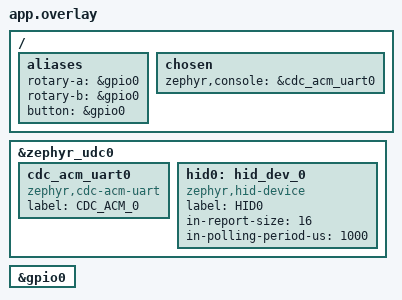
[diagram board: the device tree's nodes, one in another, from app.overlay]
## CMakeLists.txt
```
cmake_minimum_required(VERSION 3.20.0)
find_package(Zephyr)
project(wknb)

target_sources(app PRIVATE src/main.c)
```

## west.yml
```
manifest:
  version: 0.12

  remotes:
    - name: zephyrproject-rtos
      url-base: https://github.com/zephyrproject-rtos

  projects:
    - name: zephyr
      remote: zephyrproject-rtos
      revision: v4.1.0
      import: true  # will auto-fetch all Zephyr dependencies

  self:
    path: app  # <-- path to your application code
```

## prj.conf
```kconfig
# Debug Configuration - USB HID + CDC ACM Console

# USB Device Support
CONFIG_USB_DEVICE_STACK=y
CONFIG_USB_DEVICE_HID=y
CONFIG_USB_DEVICE_PRODUCT="WKNB - Wake Knob Debug"
CONFIG_USB_DEVICE_MANUFACTURER="Cyan Delta"
CONFIG_USB_DEVICE_VID=0xF055
CONFIG_USB_DEVICE_PID=0x2201
CONFIG_USB_SELF_POWERED=y
CONFIG_USB_COMPOSITE_DEVICE=y
CONFIG_USB_DEVICE_REMOTE_WAKEUP=y

# GPIO Support
CONFIG_GPIO=y
CONFIG_GPIO_ENABLE_DISABLE_INTERRUPT=y

# Enable printk and logging for debugging
CONFIG_CONSOLE=y
CONFIG_LOG=y
CONFIG_PRINTK=y

# USB CDC ACM Console (via micro-USB port)
CONFIG_SERIAL=y
CONFIG_USB_CDC_ACM=y

# Debug build flag
CONFIG_DEBUG=y
```

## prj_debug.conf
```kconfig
# Debug Configuration - USB HID + CDC ACM Console

# USB Device Support
CONFIG_USB_DEVICE_STACK=y
CONFIG_USB_DEVICE_HID=y
CONFIG_USB_DEVICE_PRODUCT="WKNB - Wake Knob Debug"
CONFIG_USB_DEVICE_MANUFACTURER="Cyan Delta"
CONFIG_USB_DEVICE_VID=0xF055
CONFIG_USB_DEVICE_PID=0x2201
CONFIG_USB_SELF_POWERED=y
CONFIG_USB_COMPOSITE_DEVICE=y

# GPIO Support
CONFIG_GPIO=y
CONFIG_GPIO_ENABLE_DISABLE_INTERRUPT=y

# Enable printk and logging for debugging
CONFIG_CONSOLE=y
CONFIG_LOG=y
CONFIG_PRINTK=y

# USB CDC ACM Console (via micro-USB port)
CONFIG_SERIAL=y
CONFIG_USB_CDC_ACM=y

# Debug build flag
CONFIG_DEBUG=y
```

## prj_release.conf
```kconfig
# Release Configuration - USB HID Only

# USB Device Support
CONFIG_USB_DEVICE_STACK=y
CONFIG_USB_DEVICE_HID=y
CONFIG_USB_DEVICE_PRODUCT="WKNB - Wake Knob"
CONFIG_USB_DEVICE_MANUFACTURER="Cyan Delta"
CONFIG_USB_DEVICE_VID=0xF055
CONFIG_USB_DEVICE_PID=0x2201
CONFIG_USB_SELF_POWERED=y
CONFIG_USB_DEVICE_REMOTE_WAKEUP=y

# GPIO Support
CONFIG_GPIO=y
CONFIG_GPIO_ENABLE_DISABLE_INTERRUPT=y

# Disable debugging features for release
# CONFIG_CONSOLE is not set
# CONFIG_LOG is not set
# CONFIG_PRINTK is not set

# No CDC ACM in release mode
# CONFIG_SERIAL is not set
# CONFIG_USB_CDC_ACM is not set
# CONFIG_USB_COMPOSITE_DEVICE is not set
```

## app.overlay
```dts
/ {
    aliases {
        rotary-a = &gpio0;
        rotary-b = &gpio0;
        button = &gpio0;
    };

    chosen {
        zephyr,console = &cdc_acm_uart0;
    };
};

&zephyr_udc0 {
    status = "okay";
    
    cdc_acm_uart0: cdc_acm_uart0 {
        compatible = "zephyr,cdc-acm-uart";
        label = "CDC_ACM_0";
    };
    
    hid0: hid_dev_0 {
        compatible = "zephyr,hid-device";
        label = "HID0";
        in-report-size = <16>;
        in-polling-period-us = <1000>;
    };
};

&gpio0 {
    status = "okay";
};
```

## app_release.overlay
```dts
/ {
    aliases {
        rotary-a = &gpio0;
        rotary-b = &gpio0;
        button = &gpio0;
    };
};

&zephyr_udc0 {
    status = "okay";
    
    hid0: hid_dev_0 {
        compatible = "zephyr,hid-device";
        label = "HID0";
        in-report-size = <16>;
        in-polling-period-us = <1000>;
    };
};

&gpio0 {
    status = "okay";
};
```

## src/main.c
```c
#include <zephyr/device.h>
#include <zephyr/drivers/gpio.h>
#include <zephyr/kernel.h>
#include <zephyr/usb/class/usb_hid.h>
#include <zephyr/usb/usb_device.h>

#ifdef CONFIG_DEBUG
#define DEBUG_PRINT(fmt, ...) printk(fmt, ##__VA_ARGS__)
#else
#define DEBUG_PRINT(fmt, ...)                                                  \
  do {                                                                         \
  } while (0)
#endif

#define ROTARY_A_PIN 14
#define ROTARY_B_PIN 15
#define BUTTON_PIN 16
#define LED_PIN 25

#define NUMBER_OF_DETENTS_PER_REPORT 6
#define LONG_PRESS_DURATION_MS 2000

static const struct gpio_dt_spec rotary_a = {
    .port = DEVICE_DT_GET(DT_NODELABEL(gpio0)),
    .pin = ROTARY_A_PIN,
    .dt_flags = GPIO_PULL_UP};
static const struct gpio_dt_spec rotary_b = {
    .port = DEVICE_DT_GET(DT_NODELABEL(gpio0)),
    .pin = ROTARY_B_PIN,
    .dt_flags = GPIO_PULL_UP};
static const struct gpio_dt_spec button = {
    .port = DEVICE_DT_GET(DT_NODELABEL(gpio0)),
    .pin = BUTTON_PIN,
    .dt_flags = GPIO_PULL_UP};
static const struct gpio_dt_spec led = {.port =
                                            DEVICE_DT_GET(DT_NODELABEL(gpio0)),
                                        .pin = LED_PIN,
                                        .dt_flags = GPIO_ACTIVE_HIGH};

static const struct device *hid_dev;
static int last_rotary_state = 0;
static int led_blink_count = 0;
static int detent_counter = 0;
static bool usb_suspended = false;
static struct gpio_callback button_cb_data;
static int64_t last_activity_time = 0;
static struct k_work_delayable long_press_work;
static bool button_pressed_flag = false;
static int64_t button_press_time = 0;

// HID Report Descriptor for Consumer Control (volume/media keys) and System
// Control (suspend)
static const uint8_t hid_report_desc[] = {
    // Consumer Control Collection
    0x05, 0x0C,       // USAGE_PAGE (Consumer Devices)
    0x09, 0x01,       // USAGE (Consumer Control)
    0xA1, 0x01,       // COLLECTION (Application)
    0x85, 0x01,       //   REPORT_ID (1)
    0x15, 0x00,       //   LOGICAL_MINIMUM (0)
    0x26, 0x9C, 0x02, //   LOGICAL_MAXIMUM (668)
    0x19, 0x00,       //   USAGE_MINIMUM (0)
    0x2A, 0x9C, 0x02, //   USAGE_MAXIMUM (668)
    0x75, 0x10,       //   REPORT_SIZE (16)
    0x95, 0x01,       //   REPORT_COUNT (1)
    0x81, 0x00,       //   INPUT (Data,Array,Abs)
    0xC0,             // END_COLLECTION

    // System Control Collection
    0x05, 0x01, // USAGE_PAGE (Generic Desktop)
    0x09, 0x80, // USAGE (System Control)
    0xA1, 0x01, // COLLECTION (Application)
    0x85, 0x02, //   REPORT_ID (2)
    0x15, 0x00, //   LOGICAL_MINIMUM (0)
    0x25, 0x01, //   LOGICAL_MAXIMUM (1)
    0x09, 0x82, //   USAGE (System Sleep)
    0x75, 0x01, //   REPORT_SIZE (1)
    0x95, 0x01, //   REPORT_COUNT (1)
    0x81, 0x06, //   INPUT (Data,Var,Rel)
    0x75, 0x07, //   REPORT_SIZE (7)
    0x95, 0x01, //   REPORT_COUNT (1)
    0x81, 0x03, //   INPUT (Cnst,Var,Abs)
    0xC0        // END_COLLECTION
};

void send_suspend_command(void) {
  if (!usb_suspended) {
    DEBUG_PRINT("Sending system suspend command\n");
    uint8_t suspend_report[] = {0x02,
                                0x01}; // Report ID 2, System Sleep bit set
    hid_int_ep_write(hid_dev, suspend_report, sizeof(suspend_report), NULL);

    // Send key release after short delay
    k_sleep(K_MSEC(15));
    uint8_t release_report[] = {0x02,
                                0x00}; // Report ID 2, System Sleep bit clear
    hid_int_ep_write(hid_dev, release_report, sizeof(release_report), NULL);

    // Visual feedback - LED blinks 5 times rapidly
    for (int i = 0; i < 5; i++) {
      gpio_pin_set_dt(&led, 1);
      k_sleep(K_MSEC(50));
      gpio_pin_set_dt(&led, 0);
      k_sleep(K_MSEC(50));
    }

    last_activity_time = k_uptime_get();
    DEBUG_PRINT("System suspend command sent\n");
  } else {
    DEBUG_PRINT("USB suspended - suspend command ignored\n");
  }
}

void long_press_work_handler(struct k_work *work) {
  if (button_pressed_flag) {
    DEBUG_PRINT("Long press detected - triggering suspend\n");
    send_suspend_command();
  }
}

void button_interrupt_handler(const struct device *dev,
                              struct gpio_callback *cb, uint32_t pins) {
  int button_state = gpio_pin_get_dt(&button);
  int64_t current_time = k_uptime_get();

  if (button_state == 0) { // Button pressed (active low with pull-up)
    DEBUG_PRINT("Button pressed at %lld ms\n", current_time);
    button_pressed_flag = true;
    button_press_time = current_time;

    // Schedule long press work
    k_work_schedule(&long_press_work, K_MSEC(LONG_PRESS_DURATION_MS));

  } else { // Button released
    int64_t press_duration = current_time - button_press_time;
    DEBUG_PRINT("Button released after %lld ms\n", press_duration);

    button_pressed_flag = false;

    // Cancel long press work
    k_work_cancel_delayable(&long_press_work);

    // Handle short press (wake-up functionality)
    if (press_duration < LONG_PRESS_DURATION_MS) {
      DEBUG_PRINT("Short press detected - checking wake-up conditions\n");
      DEBUG_PRINT("USB suspended: %s, Remote wakeup enabled: %s\n",
                  usb_suspended ? "YES" : "NO",
                  usb_get_remote_wakeup_status() ? "YES" : "NO");

      if (usb_suspended && usb_get_remote_wakeup_status()) {
        DEBUG_PRINT("Attempting USB wake-up...\n");
        int ret = usb_wakeup_request();
        if (ret == 0) {
          DEBUG_PRINT("USB wake-up request successful!\n");
          gpio_pin_set_dt(&led, 1);
          k_sleep(K_MSEC(100));
          gpio_pin_set_dt(&led, 0);
        } else {
          DEBUG_PRINT("USB wake-up request failed: %d\n", ret);
        }
      } else {
        DEBUG_PRINT(
            "Wake-up conditions not met - device not suspended or wake-up not "
            "enabled\n");
      }
    }
  }
}
void usb_status_cb(enum usb_dc_status_code status, const uint8_t *param) {
  switch (status) {
  case USB_DC_SUSPEND:
    usb_suspended = true;
    DEBUG_PRINT("USB SUSPENDED - wake-up now possible\n");
    break;
  case USB_DC_RESUME:
    usb_suspended = false;
    DEBUG_PRINT("USB RESUMED - wake-up no longer needed\n");
    break;
  case USB_DC_CONFIGURED:
    DEBUG_PRINT("USB CONFIGURED - device ready, remote wakeup: %s\n",
                usb_get_remote_wakeup_status() ? "YES" : "NO");
    // Just reset activity time, let keep-alive mechanism handle staying awake
    last_activity_time = k_uptime_get();
    break;
  case USB_DC_CONNECTED:
    DEBUG_PRINT("USB CONNECTED - enumeration starting\n");
    break;
  case USB_DC_DISCONNECTED:
    usb_suspended = false;
    last_activity_time = 0;
    DEBUG_PRINT("USB DISCONNECTED - resetting state\n");
    break;
  case USB_DC_RESET:
    usb_suspended = false;
    last_activity_time = 0;
    DEBUG_PRINT("USB RESET - reinitializing, remote wakeup: %s\n",
                usb_get_remote_wakeup_status() ? "YES" : "NO");
    break;
  default:
    DEBUG_PRINT("USB status change: %d\n", status);
    break;
  }
}

void send_usb_keepalive(void) {
  static uint8_t keepalive[] = {0x01, 0x00, 0x00};
  hid_int_ep_write(hid_dev, keepalive, sizeof(keepalive), NULL);
  last_activity_time = k_uptime_get();
  DEBUG_PRINT("Sent USB keep-alive\n");
}

int main(void) {
  int ret;

  // Small delay to let system stabilize before USB initialization
  k_sleep(K_MSEC(100));

  DEBUG_PRINT("=== WKNB USB Wake-up Device Starting ===\n");
  DEBUG_PRINT("Starting wknb initialization...\n");

  // Initialize USB HID
  hid_dev = device_get_binding("HID_0");
  if (hid_dev == NULL) {
    DEBUG_PRINT("ERROR: Failed to get HID device binding\n");
    return -1;
  }
  DEBUG_PRINT("HID device binding successful\n");

  usb_hid_register_device(hid_dev, hid_report_desc, sizeof(hid_report_desc),
                          NULL);
  DEBUG_PRINT("HID device registered\n");

  ret = usb_hid_init(hid_dev);
  if (ret != 0) {
    DEBUG_PRINT("ERROR: USB HID init failed: %d\n", ret);
    return -1;
  }
  DEBUG_PRINT("USB HID init successful\n");

  ret = usb_enable(usb_status_cb);
  if (ret != 0) {
    DEBUG_PRINT("ERROR: USB enable failed: %d\n", ret);
    return -1;
  }
  DEBUG_PRINT("USB enabled successfully\n");

  // Configure GPIO pins
  if (!device_is_ready(rotary_a.port) || !device_is_ready(rotary_b.port) ||
      !device_is_ready(button.port) || !device_is_ready(led.port)) {
    DEBUG_PRINT("ERROR: GPIO devices not ready\n");
    return -1;
  }
  DEBUG_PRINT("GPIO devices ready\n");

  ret = gpio_pin_configure_dt(&rotary_a, GPIO_INPUT);
  if (ret != 0) {
    DEBUG_PRINT("ERROR: Failed to configure rotary_a: %d\n", ret);
    return -1;
  }
  ret = gpio_pin_configure_dt(&rotary_b, GPIO_INPUT);
  if (ret != 0) {
    DEBUG_PRINT("ERROR: Failed to configure rotary_b: %d\n", ret);
    return -1;
  }
  ret = gpio_pin_configure_dt(&button, GPIO_INPUT | GPIO_INT_EDGE_BOTH);
  if (ret != 0) {
    DEBUG_PRINT("ERROR: Failed to configure button: %d\n", ret);
    return -1;
  }
  ret = gpio_pin_configure_dt(&led, GPIO_OUTPUT_INACTIVE);
  if (ret != 0) {
    DEBUG_PRINT("ERROR: Failed to configure LED: %d\n", ret);
    return -1;
  }
  DEBUG_PRINT("GPIO pins configured successfully\n");

  // Initialize long press work
  k_work_init_delayable(&long_press_work, long_press_work_handler);
  DEBUG_PRINT("Long press work initialized\n");

  // Initial LED test - blink 3 times to show device is working
  DEBUG_PRINT("Starting LED blink test\n");
  for (int i = 0; i < 3; i++) {
    DEBUG_PRINT("LED blink %d\n", i + 1);
    gpio_pin_set_dt(&led, 1);
    k_sleep(K_MSEC(200));
    gpio_pin_set_dt(&led, 0);
    k_sleep(K_MSEC(200));
    send_usb_keepalive();
  }
  DEBUG_PRINT("LED blink test completed\n");

  // Configure button interrupt
  gpio_init_callback(&button_cb_data, button_interrupt_handler,
                     BIT(button.pin));
  ret = gpio_add_callback(button.port, &button_cb_data);
  if (ret != 0) {
    DEBUG_PRINT("ERROR: Failed to add button callback: %d\n", ret);
    return -1;
  }

  ret = gpio_pin_interrupt_configure_dt(&button, GPIO_INT_EDGE_BOTH);
  if (ret != 0) {
    DEBUG_PRINT("ERROR: Failed to configure button interrupt: %d\n", ret);
    return -1;
  }
  DEBUG_PRINT("Button interrupt configured successfully\n");

  // Initialize rotary encoder state
  int a_val = gpio_pin_get_dt(&rotary_a);
  int b_val = gpio_pin_get_dt(&rotary_b);
  last_rotary_state = (b_val << 1) | a_val;
  DEBUG_PRINT("Rotary encoder initialized, entering main loop\n");

  while (1) {
    // Poll rotary encoder
    a_val = gpio_pin_get_dt(&rotary_a);
    b_val = gpio_pin_get_dt(&rotary_b);
    int current_state = (b_val << 1) | a_val;

    // Send periodic keep-alive to prevent USB suspend (every 500ms)
    int64_t current_time = k_uptime_get();
    if (!usb_suspended && (current_time - last_activity_time) > 500) {
      send_usb_keepalive();
    }

    if (current_state != last_rotary_state) {
      // Quadrature state transition table
      static const int8_t transition_table[4][4] = {/*00*/ {0, 1, -1, 0},
                                                    /*01*/ {-1, 0, 0, 1},
                                                    /*10*/ {1, 0, 0, -1},
                                                    /*11*/ {0, -1, 1, 0}};

      int8_t direction = transition_table[last_rotary_state][current_state];

      if (direction != 0) {
        led_blink_count = direction > 0 ? 1 : 2;

        // Increment detent counter in the direction of rotation
        detent_counter += direction;

        // Send HID report only after required detents in same direction
        if (detent_counter >= NUMBER_OF_DETENTS_PER_REPORT) {
          DEBUG_PRINT("Volume Up detected (detent_counter: %d)\n",
                      detent_counter);

          // Only send volume commands when USB is not suspended
          if (!usb_suspended) {
            uint8_t report[] = {0x01, 0xE9, 0x00}; // Volume Up
            hid_int_ep_write(hid_dev, report, sizeof(report), NULL);

            // Send key release after short delay
            k_sleep(K_MSEC(15));
            uint8_t release[] = {0x01, 0x00, 0x00};
            hid_int_ep_write(hid_dev, release, sizeof(release), NULL);

            // Update activity time
            last_activity_time = k_uptime_get();
          } else {
            DEBUG_PRINT("USB suspended - volume command ignored\n");
          }

          // Reset counter by number of detents per report
          detent_counter -= NUMBER_OF_DETENTS_PER_REPORT;
        } else if (detent_counter <= -NUMBER_OF_DETENTS_PER_REPORT) {
          DEBUG_PRINT("Volume Down detected (detent_counter: %d)\n",
                      detent_counter);

          // Only send volume commands when USB is not suspended
          if (!usb_suspended) {
            uint8_t report[] = {0x01, 0xEA, 0x00}; // Volume Down
            hid_int_ep_write(hid_dev, report, sizeof(report), NULL);

            // Send key release after short delay
            k_sleep(K_MSEC(15));
            uint8_t release[] = {0x01, 0x00, 0x00};
            hid_int_ep_write(hid_dev, release, sizeof(release), NULL);

            // Update activity time
            last_activity_time = k_uptime_get();
          } else {
            DEBUG_PRINT("USB suspended - volume command ignored\n");
          }

          // Reset counter by number of detents per report
          detent_counter += NUMBER_OF_DETENTS_PER_REPORT;
        }
      }

      last_rotary_state = current_state;
    }

    k_sleep(K_MSEC(10));
  }

  return 0;
}
```
